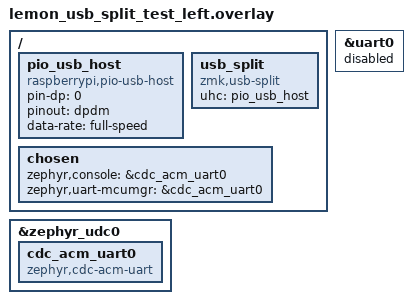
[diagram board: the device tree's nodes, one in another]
/*
 * Copyright (c) 2026 The ZMK Contributors
 * SPDX-License-Identifier: MIT
 *
 * Central side: drive UHC on the Lemon Wired Link USB-C port (GP0).
 */

#include "lemon_usb_split_test.dtsi"

&uart0 {
    status = "disabled";
};

/ {
    pio_usb_host: pio_usb_host {
        compatible = "raspberrypi,pio-usb-host";
        pin-dp = <0>;
        pinout = "dpdm";
        data-rate = "full-speed";
        status = "okay";
    };

    usb_split: usb_split {
        compatible = "zmk,usb-split";
        uhc = <&pio_usb_host>;
    };

    chosen {
        zephyr,console = &cdc_acm_uart0;
        zephyr,uart-mcumgr = &cdc_acm_uart0;
    };
};

/* Serial console on the native USB-C port via the legacy USBD CDC ACM. */
&zephyr_udc0 {
    cdc_acm_uart0: cdc_acm_uart0 {
        compatible = "zephyr,cdc-acm-uart";
    };
};
